VERSION ""

NS_ :

BS_:

BU_: MOMENTUM LISTENER REQUESTER

BO_ 32 state: 2 MOMENTUM
 SG_ system_state : 0|8@1+ (1,0) [0|255] ""  LISTENER
 SG_ mcu_temperature : 8|8@1+ (1,-40) [-40|215] "degC"  LISTENER

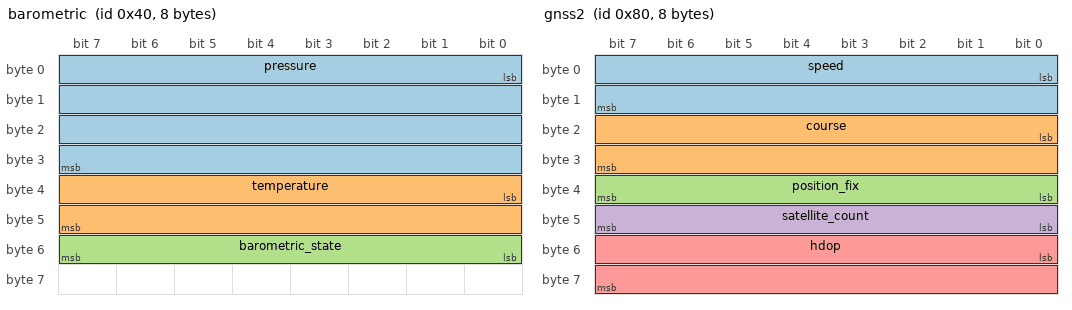
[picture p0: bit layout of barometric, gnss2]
BO_ 64 barometric: 8 MOMENTUM
 SG_ pressure : 0|32@1+ (0.00566,30000) [30000|24339514.8897] "Pa"  LISTENER
 SG_ temperature : 32|16@1+ (0.0019074,-40) [-40|85] "degC"  LISTENER
 SG_ barometric_state : 48|8@1+ (1,0) [0|255] "enum"  LISTENER

BO_ 96 gnss1: 8 MOMENTUM
 SG_ latitude : 0|32@1- (4.1909516E-08,0) [-90|90] "deg"  LISTENER
 SG_ longitude : 32|32@1- (8.3819032E-08,0) [-180|180] "deg"  LISTENER

BO_ 128 gnss2: 8 MOMENTUM
 SG_ speed : 0|16@1+ (0.01,0) [0|655.35] "knots"  LISTENER
 SG_ course : 16|16@1+ (0.01,0) [0|655.35] "deg"  LISTENER
 SG_ position_fix : 32|8@1+ (1,0) [0|255] ""  LISTENER
 SG_ satellite_count : 40|8@1+ (1,0) [0|255] "count"  LISTENER
 SG_ hdop : 48|16@1+ (0.01,0) [0|655.35] ""  LISTENER

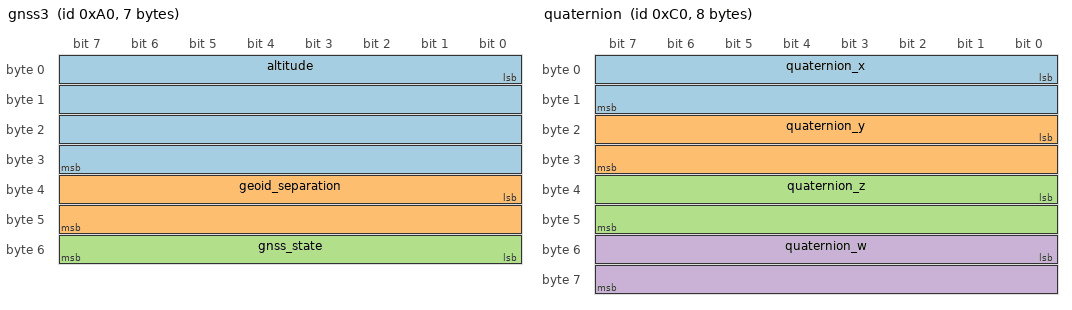
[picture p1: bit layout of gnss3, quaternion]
BO_ 160 gnss3: 7 MOMENTUM
 SG_ altitude : 0|32@1- (0.01,-150) [-150|20000] "m"  LISTENER
 SG_ geoid_separation : 32|16@1- (0.01,0) [-327.67|327.67] "m"  LISTENER
 SG_ gnss_state : 48|8@1+ (1,0) [0|255] ""  LISTENER

BO_ 192 quaternion: 8 MOMENTUM
 SG_ quaternion_x : 0|16@1- (3.05185E-05,0) [-0.99998|0.99998] "q15"  LISTENER
 SG_ quaternion_y : 16|16@1- (3.05185E-05,0) [-0.99998|0.99998] "q15"  LISTENER
 SG_ quaternion_z : 32|16@1- (3.05185E-05,0) [-0.99998|0.99998] "q15"  LISTENER
 SG_ quaternion_w : 48|16@1- (3.05185E-05,0) [-0.99998|0.99998] "q15"  LISTENER

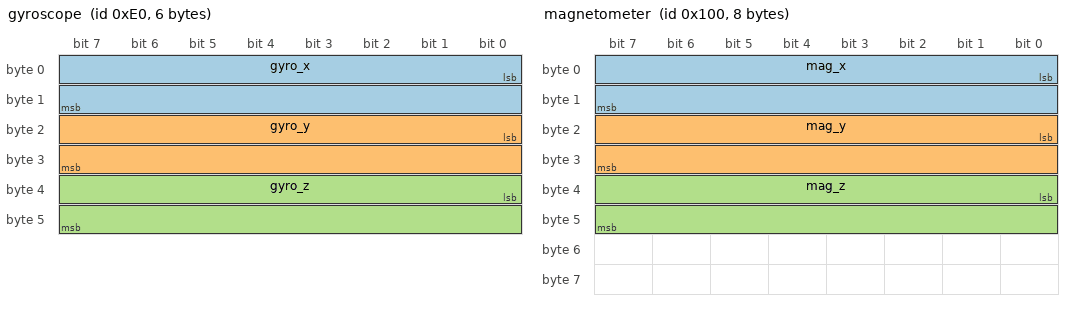
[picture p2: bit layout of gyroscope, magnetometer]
BO_ 224 gyroscope: 6 MOMENTUM
 SG_ gyro_x : 0|16@1- (0.0625,0) [-2000|2000] "deg/s"  LISTENER
 SG_ gyro_y : 16|16@1- (0.0625,0) [-2000|2000] "deg/s"  LISTENER
 SG_ gyro_z : 32|16@1- (0.0625,0) [-2000|2000] "deg/s"  LISTENER

BO_ 256 magnetometer: 8 MOMENTUM
 SG_ mag_x : 0|16@1- (0.0625,0) [-2000|2000] "uT"  LISTENER
 SG_ mag_y : 16|16@1- (0.0625,0) [-2000|2000] "uT"  LISTENER
 SG_ mag_z : 32|16@1- (0.0625,0) [-2000|2000] "uT"  LISTENER

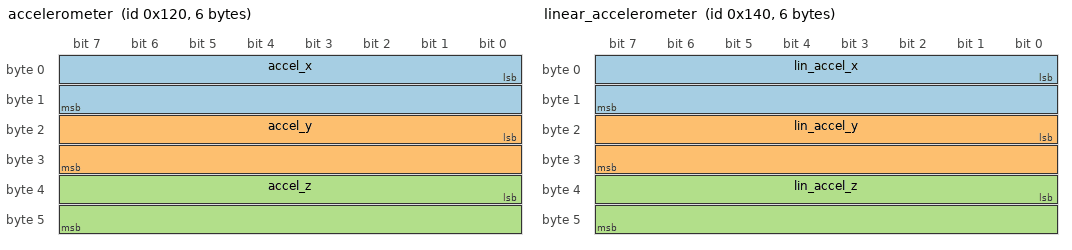
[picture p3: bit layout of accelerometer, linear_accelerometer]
BO_ 288 accelerometer: 6 MOMENTUM
 SG_ accel_x : 0|16@1- (0.0047889,0) [-156.9|156.9] "m/s^2"  LISTENER
 SG_ accel_y : 16|16@1- (0.0047889,0) [-156.9|156.9] "m/s^2"  LISTENER
 SG_ accel_z : 32|16@1- (0.0047889,0) [-156.9|156.9] "m/s^2"  LISTENER

BO_ 320 linear_accelerometer: 6 MOMENTUM
 SG_ lin_accel_x : 0|16@1- (0.0047889,0) [-156.9|156.9] "m/s^2"  LISTENER
 SG_ lin_accel_y : 16|16@1- (0.0047889,0) [-156.9|156.9] "m/s^2"  LISTENER
 SG_ lin_accel_z : 32|16@1- (0.0047889,0) [-156.9|156.9] "m/s^2"  LISTENER

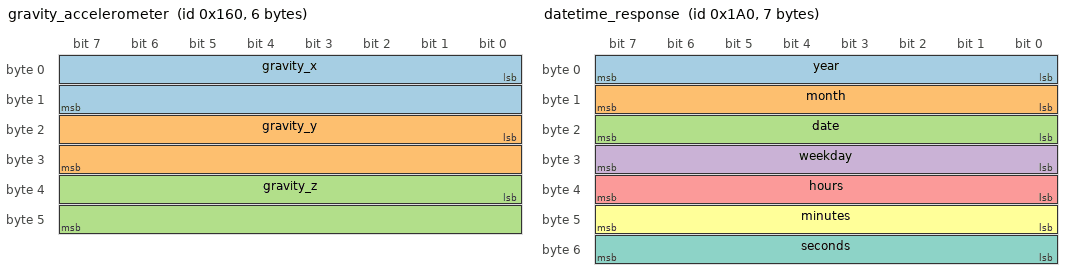
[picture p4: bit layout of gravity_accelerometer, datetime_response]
BO_ 352 gravity_accelerometer: 6 MOMENTUM
 SG_ gravity_x : 0|16@1- (0.0002994,0) [-9.81|9.81] "m/s^2"  LISTENER
 SG_ gravity_y : 16|16@1- (0.0002994,0) [-9.81|9.81] "m/s^2"  LISTENER
 SG_ gravity_z : 32|16@1- (0.0002994,0) [-9.81|9.81] "m/s^2"  LISTENER

BO_ 384 datetime_get: 0 REQUESTER

BO_ 416 datetime_response: 7 MOMENTUM
 SG_ year : 0|8@1+ (1,0) [0|99] "year"  REQUESTER
 SG_ month : 8|8@1+ (1,0) [1|12] "month"  REQUESTER
 SG_ date : 16|8@1+ (1,0) [1|31] "day"  REQUESTER
 SG_ weekday : 24|8@1+ (1,0) [1|7] "weekday"  REQUESTER
 SG_ hours : 32|8@1+ (1,0) [0|23] "hour"  REQUESTER
 SG_ minutes : 40|8@1+ (1,0) [0|59] "min"  REQUESTER
 SG_ seconds : 48|8@1+ (1,0) [0|59] "sec"  REQUESTER

BO_ 448 gnss_utc_get: 0 REQUESTER

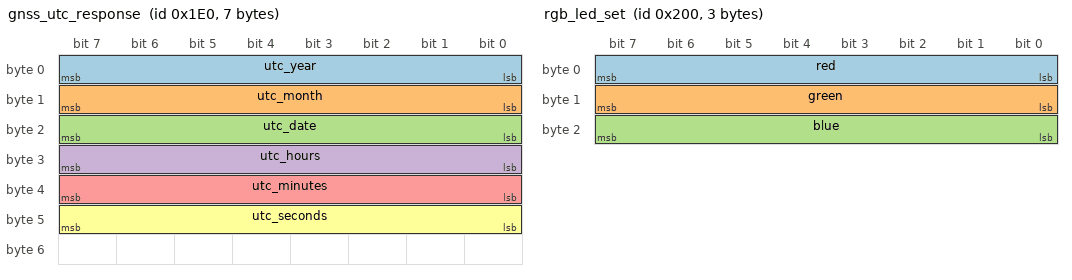
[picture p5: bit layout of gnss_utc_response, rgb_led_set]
BO_ 480 gnss_utc_response: 7 MOMENTUM
 SG_ utc_year : 0|8@1+ (1,0) [0|99] "year"  REQUESTER
 SG_ utc_month : 8|8@1+ (1,0) [1|12] "month"  REQUESTER
 SG_ utc_date : 16|8@1+ (1,0) [1|31] "day"  REQUESTER
 SG_ utc_hours : 24|8@1+ (1,0) [0|23] "hour"  REQUESTER
 SG_ utc_minutes : 32|8@1+ (1,0) [0|59] "min"  REQUESTER
 SG_ utc_seconds : 40|8@1+ (1,0) [0|59] "sec"  REQUESTER

BO_ 512 rgb_led_set: 3 REQUESTER
 SG_ red : 0|8@1+ (1,0) [0|255] ""  MOMENTUM
 SG_ green : 8|8@1+ (1,0) [0|255] ""  MOMENTUM
 SG_ blue : 16|8@1+ (1,0) [0|255] ""  MOMENTUM

BO_ 960 version_get: 0 REQUESTER

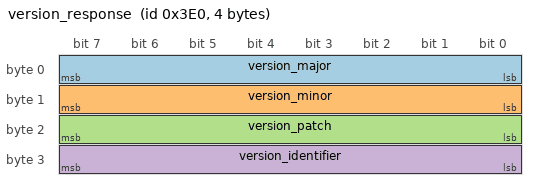
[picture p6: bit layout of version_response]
BO_ 992 version_response: 4 MOMENTUM
 SG_ version_major : 0|8@1+ (1,0) [0|255] "major"  REQUESTER
 SG_ version_minor : 8|8@1+ (1,0) [0|255] "minor"  REQUESTER
 SG_ version_patch : 16|8@1+ (1,0) [0|255] "patch"  REQUESTER
 SG_ version_identifier : 24|8@1+ (1,0) [0|255] "ascii"  REQUESTER

BA_DEF_  "BusType" STRING ;
BA_DEF_DEF_  "BusType" "CAN";
